# STM32U5xx register map
File version: 1.3
Registers are 32-bit, read-write, reset 0x0 unless marked. A register's access mark holds for its fields unless they carry their own. Offsets are from the block's base; [hi:lo] are bit positions; {n}, {i} and the like mark numbered series.

## FLASH
Base 0x40022000
Same registers: SEC_FLASH 0x50022000
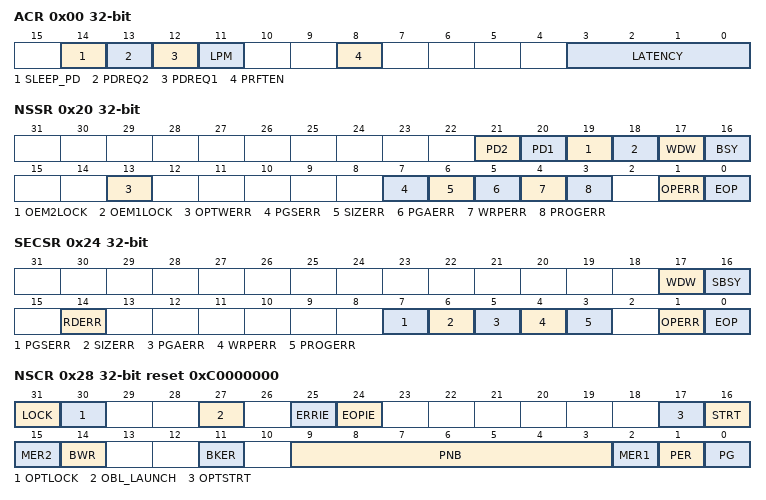
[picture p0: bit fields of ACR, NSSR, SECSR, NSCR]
0x00 ACR — Access control register
  [14] SLEEP_PD — Flash memory power-down mode during Sleep mode
  [13] PDREQ2 — Bank 2 power-down mode request
  [12] PDREQ1 — Bank 1 power-down mode request
  [11] LPM — Low-power read mode
  [8] PRFTEN — Prefetch enable
  [3:0] LATENCY
0x08 NSKEYR wo — Flash non-secure key register
  [31:0] NSKEY — Flash memory non-secure key
0x0C SECKEYR wo — Flash secure key register
  [31:0] SECKEY — Flash memory secure key
0x10 OPTKEYR wo — Flash option key register
  [31:0] OPTKEY
0x18 PDKEY1R wo — FLASH bank 1 power-down key register
  [31:0] PDKEY1 — Bank 1 power-down key
0x1C PDKEY2R wo — FLASH bank 2 power-down key register
  [31:0] PDKEY2 — Bank 2 power-down key
0x20 NSSR access per field — Flash non-secure status register
  [21] PD2 ro — Bank 2 in power-down mode
  [20] PD1 ro — Bank 1 in power-down mode
  [19] OEM2LOCK ro
  [18] OEM1LOCK ro
  [17] WDW ro — Non-secure wait data to write
  [16] BSY ro — Non-secure busy
  [13] OPTWERR rw — Option write error
  [7] PGSERR rw — Non-secure programming sequence error
  [6] SIZERR rw — Non-secure size error
  [5] PGAERR rw — Non-secure programming alignment error
  [4] WRPERR rw — Non-secure write protection error
  [3] PROGERR rw — Non-secure programming error
  [1] OPERR rw — Non-secure operation error
  [0] EOP rw — Non-secure end of operation
0x24 SECSR access per field — Flash secure status register
  [17] WDW ro — Secure wait data to write
  [16] SBSY ro — Secure busy
  [14] RDERR rw — Secure readout protection error
  [7] PGSERR rw — Secure programming sequence error
  [6] SIZERR rw — Secure size error
  [5] PGAERR rw — Secure programming alignment error
  [4] WRPERR rw — Secure write protection error
  [3] PROGERR rw — Secure programming error
  [1] OPERR rw — Secure operation error
  [0] EOP rw — Secure end of operation
0x28 NSCR reset 0xC0000000 — Flash non-secure control register
  [31] LOCK — Non-secure lock
  [30] OPTLOCK — Options Lock
  [27] OBL_LAUNCH — Force the option byte loading
  [25] ERRIE — Non-secure error interrupt enable
  [24] EOPIE — Non-secure end of operation interrupt enable
  [17] OPTSTRT — Options modification start
  [16] STRT — Non-secure start
  [15] MER2 — Non-secure bank 2 mass erase
  [14] BWR — Non-secure burst write programming mode
  [11] BKER — Non-secure bank selection for page erase
  [9:3] PNB — Non-secure page number selection
  [2] MER1 — Non-secure bank 1 mass erase
  [1] PER — Non-secure page erase
  [0] PG — Non-secure programming
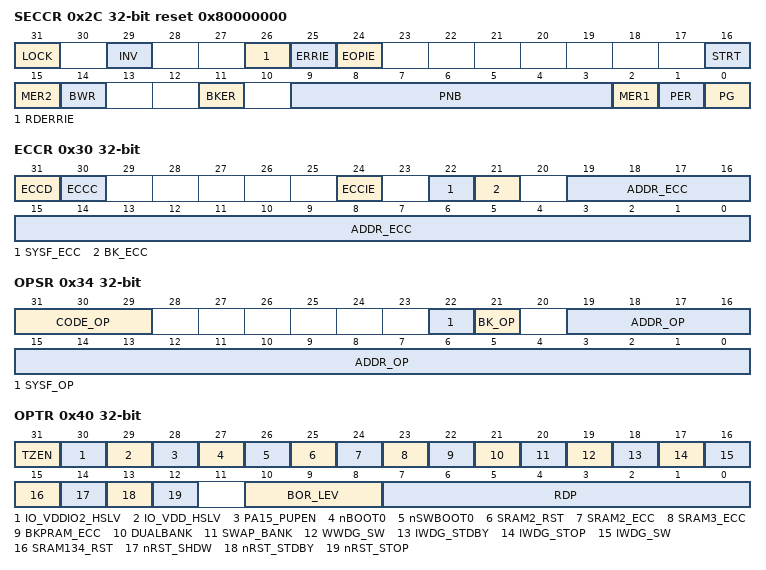
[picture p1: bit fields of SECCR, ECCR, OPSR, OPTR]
0x2C SECCR reset 0x80000000 — Flash secure control register
  [31] LOCK — secure lock
  [29] INV — Flash memory security state invert
  [26] RDERRIE — Secure PCROP read error interrupt enable
  [25] ERRIE — secure error interrupt enable
  [24] EOPIE — Non-secure end of operation interrupt enable
  [16] STRT — Secure start
  [15] MER2 — secure bank 2 mass erase
  [14] BWR — secure burst write programming mode
  [11] BKER — secure bank selection for page erase
  [9:3] PNB — secure page number selection
  [2] MER1 — secure bank 1 mass erase
  [1] PER — secure page erase
  [0] PG — secure programming
0x30 ECCR access per field — Flash ECC register
  [31] ECCD rw — ECC detection
  [30] ECCC rw — ECC correction
  [24] ECCIE rw — ECC correction interrupt enable
  [22] SYSF_ECC ro — System Flash memory ECC fail
  [21] BK_ECC ro — ECC fail bank
  [19:0] ADDR_ECC ro — ECC fail address
0x34 OPSR ro — Flash operation status register
  [31:29] CODE_OP — Flash memory operation code
  [22] SYSF_OP — Operation in system Flash memory interrupted
  [21] BK_OP — Interrupted operation bank
  [19:0] ADDR_OP — Interrupted operation address
0x40 OPTR — Flash option register
  [31] TZEN — Global TrustZone security enable
  [30] IO_VDDIO2_HSLV — High-speed IO at low VDDIO2 voltage configuration bit
  [29] IO_VDD_HSLV — High-speed IO at low VDD voltage configuration bit
  [28] PA15_PUPEN
  [27] nBOOT0
  [26] nSWBOOT0
  [25] SRAM2_RST — SRAM2 Erase when system reset
  [24] SRAM2_ECC — SRAM2 ECC detection and correction enable
  [23] SRAM3_ECC — SRAM3 ECC detection and correction enable
  [22] BKPRAM_ECC — Backup RAM ECC detection and correction enable
  [21] DUALBANK — Dual-bank on 1-Mbyte and 512-Kbyte Flash memory devices
  [20] SWAP_BANK
  [19] WWDG_SW — Window watchdog selection
  [18] IWDG_STDBY — Independent watchdog counter freeze in Standby mode
  [17] IWDG_STOP — Independent watchdog counter freeze in Stop mode
  [16] IWDG_SW — Independent watchdog selection
  [15] SRAM134_RST — SRAM1, SRAM3 and SRAM4 erase upon system reset
  [14] nRST_SHDW
  [13] nRST_STDBY
  [12] nRST_STOP
  [10:8] BOR_LEV — BOR reset Level
  [7:0] RDP — Read protection level
0x44 NSBOOTADD0R reset 0xF — Flash non-secure boot address 0 register
  [31:7] NSBOOTADD0 — Non-secure boot base address 0
0x48 NSBOOTADD1R reset 0xF — Flash non-secure boot address 1 register
  [31:7] NSBOOTADD1 — Non-secure boot address 1
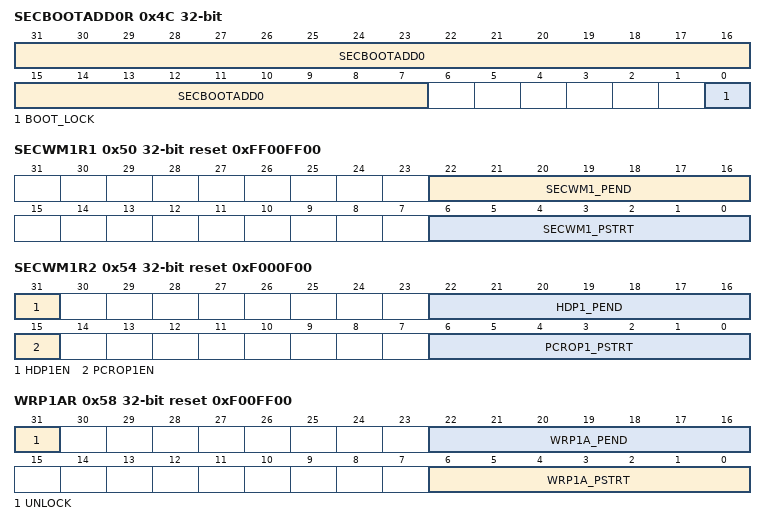
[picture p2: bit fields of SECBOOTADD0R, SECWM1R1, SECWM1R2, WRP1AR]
0x4C SECBOOTADD0R — FFlash secure boot address 0 register
  [31:7] SECBOOTADD0, [0] BOOT_LOCK
0x50 SECWM1R1 reset 0xFF00FF00 — Flash bank 1 secure watermak1 register
  [22:16] SECWM1_PEND, [6:0] SECWM1_PSTRT
0x54 SECWM1R2 reset 0xF000F00 — Flash secure watermak1 register 2
  [31] HDP1EN, [22:16] HDP1_PEND, [15] PCROP1EN, [6:0] PCROP1_PSTRT
0x58 WRP1AR reset 0xF00FF00 — Flash Bank 1 WRP area A address register
  [31] UNLOCK — Bank 1 WPR first area A unlock
  [22:16] WRP1A_PEND
  [6:0] WRP1A_PSTRT
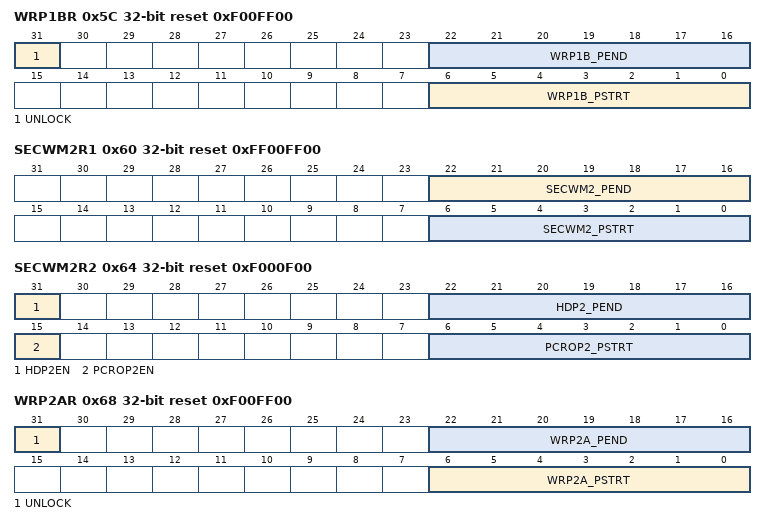
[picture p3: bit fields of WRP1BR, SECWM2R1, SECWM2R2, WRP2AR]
0x5C WRP1BR reset 0xF00FF00 — FLASH WRP1 area B address register
  [31] UNLOCK — Bank 1 WPR second area B unlock
  [22:16] WRP1B_PEND
  [6:0] WRP1B_PSTRT
0x60 SECWM2R1 reset 0xFF00FF00 — Flash secure watermak2 register 1
  [22:16] SECWM2_PEND, [6:0] SECWM2_PSTRT
0x64 SECWM2R2 reset 0xF000F00 — Flash secure watermak2 register2
  [31] HDP2EN, [22:16] HDP2_PEND, [15] PCROP2EN, [6:0] PCROP2_PSTRT
0x68 WRP2AR reset 0xF00FF00 — Flash WPR2 area A address register
  [31] UNLOCK — Bank 2 WPR first area A unlock
  [22:16] WRP2A_PEND
  [6:0] WRP2A_PSTRT
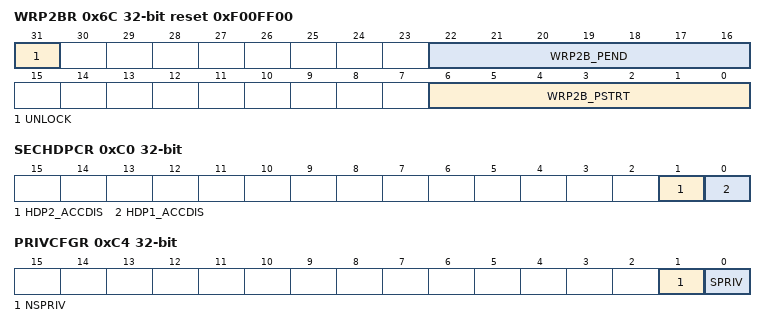
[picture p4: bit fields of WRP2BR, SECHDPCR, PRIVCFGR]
0x6C WRP2BR reset 0xF00FF00 — Flash WPR2 area B address register
  [31] UNLOCK — Bank 2 WPR second area B unlock
  [22:16] WRP2B_PEND
  [6:0] WRP2B_PSTRT
0x70 OEM1KEYR1 wo — FLASH OEM1 key register 1
  [31:0] OEM1KEY — OEM1 least significant bytes key
0x74 OEM1KEYR2 wo — FLASH OEM1 key register 2
  [31:0] OEM1KEY — OEM1 most significant bytes key
0x78 OEM2KEYR1 wo — FLASH OEM2 key register 1
  [31:0] OEM2KEY — OEM2 least significant bytes key
0x7C OEM2KEYR2 wo — FLASH OEM2 key register 2
  [31:0] OEM2KEY — OEM2 most significant bytes key
{0x7C+4i} SEC1BBR{i} (i=1..4) — FLASH secure block based bank 1 register
  [31:0] SEC1BB
{0x9C+4i} SEC2BBR{i} (i=1..4) — FLASH secure block based bank 2 register
  [31:0] SEC2BB
0xC0 SECHDPCR — FLASH secure HDP control register
  [1] HDP2_ACCDIS, [0] HDP1_ACCDIS
0xC4 PRIVCFGR — FLASH privilege configuration register
  [1] NSPRIV — Privileged protection for non-secure registers
  [0] SPRIV — Privileged protection for secure registers
{0xCC+4i} PRIV1BBR{i} (i=1..4) — FLASH privilege block based bank 1 register
  [31:0] PRIV1BB
{0xEC+4i} PRIV2BBR{i} (i=1..4) — FLASH privilege block based bank 2 register
  [31:0] PRIV2BB
